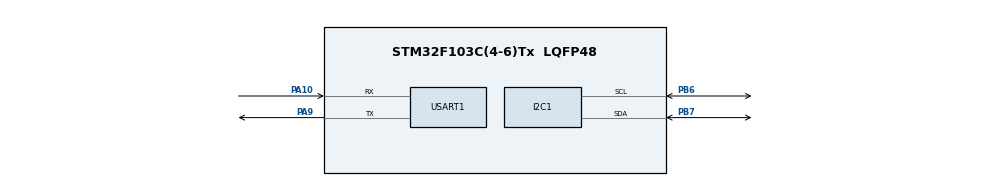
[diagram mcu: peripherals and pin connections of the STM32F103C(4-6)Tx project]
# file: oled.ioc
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Mcu.Family=STM32F1
Mcu.Name=STM32F103C(4-6)Tx
Mcu.Package=LQFP48
NVIC.PriorityGroup=NVIC_PRIORITYGROUP_4
PA10.Mode=Asynchronous
PA10.Signal=USART1_RX
PA13.Mode=Serial_Wire
PA13.Signal=SYS_JTMS-SWDIO
PA14.Mode=Serial_Wire
PA14.Signal=SYS_JTCK-SWCLK
PA9.Mode=Asynchronous
PA9.Signal=USART1_TX
PB6.Mode=I2C
PB6.Signal=I2C1_SCL
PB7.Mode=I2C
PB7.Signal=I2C1_SDA
ProjectManager.HeapSize=0x200
ProjectManager.StackSize=0x400
ProjectManager.TargetToolchain=MDK-ARM V5.32
RCC.APB1Freq_Value=8000000
RCC.APB2Freq_Value=8000000
USART1.VirtualMode=VM_ASYNC
board=custom

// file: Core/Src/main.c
/* USER CODE BEGIN Header */
/**
  ******************************************************************************
  * @file           : main.c
  * @brief          : Main program body
  ******************************************************************************
  * @attention
  *
  * Copyright (c) 2026 STMicroelectronics.
  * All rights reserved.
  *
  * This software is licensed under terms that can be found in the LICENSE file
  * in the root directory of this software component.
  * If no LICENSE file comes with this software, it is provided AS-IS.
  *
  ******************************************************************************
  */
/* USER CODE END Header */
#include "main.h"

/* USER CODE BEGIN Includes */
#include <stdio.h>
#include <string.h>
#include <stdbool.h>
#include "ssd1306.h"
#include "fonts.h"
/* USER CODE END Includes */

I2C_HandleTypeDef hi2c1;

UART_HandleTypeDef huart1;

float lower_t = 100;

float higher_t = 0;

void SystemClock_Config(void);
static void MX_GPIO_Init(void);
static void MX_I2C1_Init(void);
static void MX_USART1_UART_Init(void);

/* USER CODE BEGIN 0 */

#define DEBUG_ENABLE 0

#if DEBUG_ENABLE
    #define DEBUG_PRINT(fmt, ...) printf("[DEBUG] %s:%d: " fmt "\r\n", __FILE__, __LINE__, ##__VA_ARGS__)
    #define DEBUG_INFO(fmt, ...)  printf("[INFO] " fmt "\r\n", ##__VA_ARGS__)
    #define DEBUG_ERR(fmt, ...)   printf("[ERROR] " fmt "\r\n", ##__VA_ARGS__)

	#ifdef __GNUC__
		#define PUTCHAR_PROTOTYPE int __io_putchar(int ch)
	#else
		#define PUTCHAR_PROTOTYPE int fputc(int ch, FILE *f)
	#endif

	PUTCHAR_PROTOTYPE
	{
		HAL_UART_Transmit(&huart1, (uint8_t *)&ch, 1, 0xFFFF);
		return ch;
	}

#else
    #define DEBUG_PRINT(fmt, ...)
    #define DEBUG_INFO(fmt, ...)
    #define DEBUG_ERR(fmt, ...)
#endif

void get_float_str(char *buf, float temp, char *pre_str, char *unit_str) {
    int32_t integral = (int32_t)temp;
    int32_t fractional = (int32_t)((temp - integral) * 100);
    if(fractional < 0) fractional = -fractional;

    // ???????,????
    sprintf(buf, "%d.%02d%s", integral, fractional, unit_str);
}

/* USER CODE END 0 */

int main(void)
{

  /* MCU Configuration--------------------------------------------------------*/

  /* Reset of all peripherals, Initializes the Flash interface and the Systick. */
  HAL_Init();

  /* Configure the system clock */
  SystemClock_Config();

  /* Initialize all configured peripherals */
  MX_GPIO_Init();
  MX_I2C1_Init();
  MX_USART1_UART_Init();
  /* USER CODE BEGIN 2 */

	DEBUG_PRINT("Initialize the thermometer\r\n");

	uint8_t channel = 0x2; // 0x01 ???? 0, 0x02 ???? 1...
	HAL_I2C_Master_Transmit(&hi2c1, 0x70 << 1, &channel, 1, 100);
	HAL_Delay(500);
	uint8_t reset_cmd = 0xFE;
	HAL_I2C_Master_Transmit(&hi2c1, 0x80, &reset_cmd, 1, 100);
	HAL_Delay(500);

	DEBUG_PRINT("Initialize the 0led\r\n");
	channel = 0x1; // 0x01 ???? 0, 0x02 ???? 1...
	HAL_I2C_Master_Transmit(&hi2c1, 0x70 << 1, &channel, 1, 100);
	HAL_Delay(500);

/*
	printf("\r\n--- I2C Bus Scanner Start ---\r\n");
  printf("Scanning channel %d\r\n", channel);
  printf("Scanning I2C1 (PB6:SCL, PB7:SDA)...\r\n");

  uint8_t count = 0;
  for (uint16_t i = 1; i < 128; i++) {
      if (HAL_I2C_IsDeviceReady(&hi2c1, (uint16_t)(i << 1), 3, 10) == HAL_OK) {
          printf("Found Device! 7-bit: 0x%02X (8-bit: 0x%02X)\r\n", i, i << 1);
          count++;
      }
  }

  if (count == 0) {
      printf("No I2C devices found. Check:\r\n1. Wiring (PB6/PB7)\r\n2. Power (3.3V)\r\n3. Pull-up Resistors\r\n");
  } else {
      printf("Scan finished. Total %d device(s) found.\r\n", count);
  }
  printf("------------------------------\r\n\r\n");
*/

  // Init lcd using one of the stm32HAL i2c typedefs
  if (ssd1306_Init(&hi2c1) != 0) {
    Error_Handler();
  }
  HAL_Delay(500);

  ssd1306_Fill(Black);
  ssd1306_UpdateScreen(&hi2c1);

  HAL_Delay(500);

  // Write data to local screenbuffer
	ssd1306_SetCursor(0, 6);
  ssd1306_WriteString("Hello", Font_7x10, White);

  ssd1306_SetCursor(0, 25);
  ssd1306_WriteString("World", Font_7x10, White);

	ssd1306_UpdateScreen(&hi2c1);

  HAL_Delay(500);

  DEBUG_PRINT("OLED Displayed: Hello World!!!\r\n");

  /* USER CODE END 2 */

  /* Infinite loop */
  /* USER CODE BEGIN WHILE */
	char temperature_str[16];
	char lower_t_str[16];
	char higher_t_str[16];
	char humidity_str[16];
	bool dis_low = true;

  while (1)
  {
		channel = 0x2; // 0x01 ???? 0, 0x02 ???? 1...
		HAL_I2C_Master_Transmit(&hi2c1, 0x70 << 1, &channel, 1, 100);
		HAL_Delay(200);

		uint8_t cmd_temp = 0xF3; // ?????? (No Hold)
    uint8_t cmd_humi = 0xF5; // ?????? (No Hold)
    uint8_t data[3];         // ?? [?8?, ?8?, ???]
    float temperature, humidity;

    // --- 1. ???? ---
    if (HAL_I2C_Master_Transmit(&hi2c1, 0x80, &cmd_temp, 1, 100) == HAL_OK)
    {
        HAL_Delay(100); // ???? > 85ms (14-bit ????)

        if (HAL_I2C_Master_Receive(&hi2c1, 0x81, data, 3, 100) == HAL_OK)
        {
            // SHT2x ??????: T = -46.85 + 175.72 * (Raw / 2^16)
            uint16_t raw_t = (data[0] << 8) | data[1];
            raw_t &= ~0x0003; // ?????????
            temperature = -46.85f + 175.72f * ((float)raw_t / 65536.0f);
            get_float_str(temperature_str, temperature, "T", "C");
						if (lower_t > temperature) {
							lower_t = temperature;
							memcpy(lower_t_str, temperature_str, 16);
						}
						if (higher_t < temperature) {
							higher_t = temperature;
							memcpy(higher_t_str, temperature_str, 16);
						}
        }
    }

    // --- 2. ???? ---
    if (HAL_I2C_Master_Transmit(&hi2c1, 0x80, &cmd_humi, 1, 100) == HAL_OK)
    {
        HAL_Delay(100); // ?????? (12-bit ? 29ms)

        if (HAL_I2C_Master_Receive(&hi2c1, 0x81, data, 3, 100) == HAL_OK)
        {
            // SHT2x ??????: RH = -6 + 125 * (Raw / 2^16)
            uint16_t raw_h = (data[0] << 8) | data[1];
            raw_h &= ~0x0003; // ?????
            humidity = -6.0f + 125.0f * ((float)raw_h / 65536.0f);
            get_float_str(humidity_str, humidity, "H", "%");
        }
    }

    HAL_GPIO_TogglePin(GPIOC, GPIO_PIN_13); // PC13 ????????
    HAL_Delay(200); // ??????

		channel = 0x1; // 0x01 ???? 0, 0x02 ???? 1...
		HAL_I2C_Master_Transmit(&hi2c1, 0x70 << 1, &channel, 1, 100);
		HAL_Delay(200);
    /* USER CODE END WHILE */

    /* USER CODE BEGIN 3 */
		ssd1306_Fill(Black);

		ssd1306_SetCursor(0, 0);
		ssd1306_WriteString("Temp:", Font_7x10, White);
		ssd1306_SetCursor(0, 10);
		ssd1306_WriteString(temperature_str, Font_7x10, White);
		ssd1306_SetCursor(0, 20);
		ssd1306_WriteString("Humi:", Font_7x10, White);
		ssd1306_SetCursor(0, 30);
		ssd1306_WriteString(humidity_str, Font_7x10, White);
		if (dis_low) {
			ssd1306_SetCursor(0, 40);
			ssd1306_WriteString("LowT", Font_7x10, White);
			ssd1306_SetCursor(0, 50);
			ssd1306_WriteString(lower_t_str, Font_7x10, White);
			dis_low = false;
		} else {
			ssd1306_SetCursor(0, 40);
			ssd1306_WriteString("HighT", Font_7x10, White);
			ssd1306_SetCursor(0, 50);
			ssd1306_WriteString(higher_t_str, Font_7x10, White);
			dis_low = true;
		}
		ssd1306_UpdateScreen(&hi2c1);
		DEBUG_PRINT("Temp:%s Humi:%s\r\n", temperature_str, humidity_str);
		HAL_Delay(200);
  }
  /* USER CODE END 3 */
}

void SystemClock_Config(void)
{
  RCC_OscInitTypeDef RCC_OscInitStruct = {0};
  RCC_ClkInitTypeDef RCC_ClkInitStruct = {0};

  /** Initializes the RCC Oscillators according to the specified parameters
  * in the RCC_OscInitTypeDef structure.
  */
  RCC_OscInitStruct.OscillatorType = RCC_OSCILLATORTYPE_HSI;
  RCC_OscInitStruct.HSIState = RCC_HSI_ON;
  RCC_OscInitStruct.HSICalibrationValue = RCC_HSICALIBRATION_DEFAULT;
  RCC_OscInitStruct.PLL.PLLState = RCC_PLL_NONE;
  if (HAL_RCC_OscConfig(&RCC_OscInitStruct) != HAL_OK)
  {
    Error_Handler();
  }

  /** Initializes the CPU, AHB and APB buses clocks
  */
  RCC_ClkInitStruct.ClockType = RCC_CLOCKTYPE_HCLK|RCC_CLOCKTYPE_SYSCLK
                              |RCC_CLOCKTYPE_PCLK1|RCC_CLOCKTYPE_PCLK2;
  RCC_ClkInitStruct.SYSCLKSource = RCC_SYSCLKSOURCE_HSI;
  RCC_ClkInitStruct.AHBCLKDivider = RCC_SYSCLK_DIV1;
  RCC_ClkInitStruct.APB1CLKDivider = RCC_HCLK_DIV1;
  RCC_ClkInitStruct.APB2CLKDivider = RCC_HCLK_DIV1;

  if (HAL_RCC_ClockConfig(&RCC_ClkInitStruct, FLASH_LATENCY_0) != HAL_OK)
  {
    Error_Handler();
  }
}

static void MX_I2C1_Init(void)
{

  hi2c1.Instance = I2C1;
  hi2c1.Init.ClockSpeed = 100000;
  hi2c1.Init.DutyCycle = I2C_DUTYCYCLE_2;
  hi2c1.Init.OwnAddress1 = 0;
  hi2c1.Init.AddressingMode = I2C_ADDRESSINGMODE_7BIT;
  hi2c1.Init.DualAddressMode = I2C_DUALADDRESS_DISABLE;
  hi2c1.Init.OwnAddress2 = 0;
  hi2c1.Init.GeneralCallMode = I2C_GENERALCALL_DISABLE;
  hi2c1.Init.NoStretchMode = I2C_NOSTRETCH_DISABLE;
  if (HAL_I2C_Init(&hi2c1) != HAL_OK)
  {
    Error_Handler();
  }

}

static void MX_USART1_UART_Init(void)
{

  huart1.Instance = USART1;
  huart1.Init.BaudRate = 115200;
  huart1.Init.WordLength = UART_WORDLENGTH_8B;
  huart1.Init.StopBits = UART_STOPBITS_1;
  huart1.Init.Parity = UART_PARITY_NONE;
  huart1.Init.Mode = UART_MODE_TX_RX;
  huart1.Init.HwFlowCtl = UART_HWCONTROL_NONE;
  huart1.Init.OverSampling = UART_OVERSAMPLING_16;
  if (HAL_UART_Init(&huart1) != HAL_OK)
  {
    Error_Handler();
  }

}

static void MX_GPIO_Init(void)
{

  /* GPIO Ports Clock Enable */
  GPIO_InitTypeDef GPIO_InitStruct = {0};

  /* GPIO Ports Clock Enable */
  __HAL_RCC_GPIOC_CLK_ENABLE();

  /*Configure GPIO pin Output Level */
  HAL_GPIO_WritePin(GPIOB, GPIO_PIN_13, GPIO_PIN_RESET);

  GPIO_InitStruct.Pin = GPIO_PIN_13;
  GPIO_InitStruct.Mode = GPIO_MODE_OUTPUT_PP;   // ????
  GPIO_InitStruct.Pull = GPIO_NOPULL;
  GPIO_InitStruct.Speed = GPIO_SPEED_FREQ_LOW;

  HAL_GPIO_Init(GPIOC, &GPIO_InitStruct);

}

void Error_Handler(void)
{
  __disable_irq();
  while (1)
  {
  }
}
